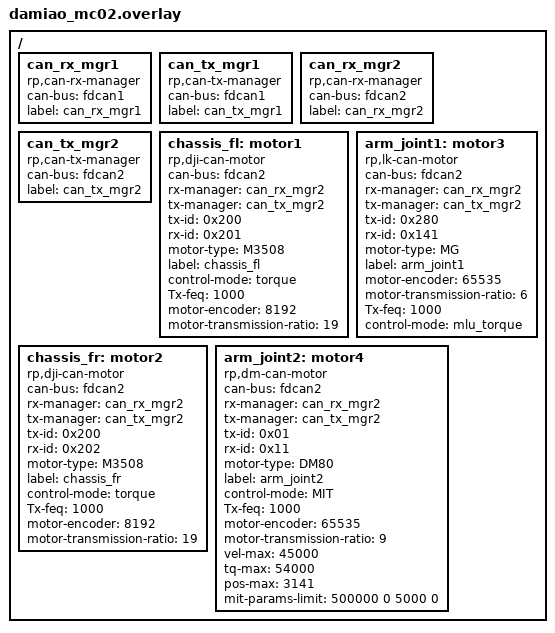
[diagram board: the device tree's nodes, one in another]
/*dts-test-motor*/
/ {
    can_rx_mgr1: can_rx_mgr1 {
        compatible = "rp,can-rx-manager";
        status = "okay";
        can-bus = <&fdcan1>;
        label = "can_rx_mgr1";
    };

    can_tx_mgr1: can_tx_mgr1 {
        compatible = "rp,can-tx-manager";
        status = "okay";
        can-bus = <&fdcan1>;
        label = "can_tx_mgr1";
    };

    can_rx_mgr2: can_rx_mgr2 {
        compatible = "rp,can-rx-manager";
        status = "okay";
        can-bus = <&fdcan2>;
        label = "can_rx_mgr2";
    };

    can_tx_mgr2: can_tx_mgr2 {
        compatible = "rp,can-tx-manager";
        status = "okay";
        can-bus = <&fdcan2>;
        label = "can_tx_mgr2";
    };

    chassis_fl:motor1{
        compatible = "rp,dji-can-motor";
        status = "okay";
        can-bus = <&fdcan2>;
        rx-manager = <&can_rx_mgr2>;
        tx-manager = <&can_tx_mgr2>;
        tx-id = <0x200>;
        rx-id = <0x201>;
        motor-type = "M3508";
        label = "chassis_fl";
        control-mode = "torque";
        Tx-feq = <1000>;
        motor-encoder = <8192>;
        motor-transmission-ratio = <19>;
    };

    chassis_fr:motor2{
        compatible = "rp,dji-can-motor";
        status = "okay";
        can-bus = <&fdcan2>;
        rx-manager = <&can_rx_mgr2>;
        tx-manager = <&can_tx_mgr2>;
        tx-id = <0x200>;
        rx-id = <0x202>;
        motor-type = "M3508";
        label = "chassis_fr";
        control-mode = "torque";
        Tx-feq = <1000>;
        motor-encoder = <8192>;
        motor-transmission-ratio = <19>;
    };

    arm_joint1:motor3{
        compatible = "rp,lk-can-motor";
        status = "okay";
        can-bus = <&fdcan2>;
        rx-manager = <&can_rx_mgr2>;
        tx-manager = <&can_tx_mgr2>;
        tx-id = <0x280>;
        rx-id = <0x141>;
        motor-type = "MG";
        label = "arm_joint1";
        motor-encoder = <65535>;
        motor-transmission-ratio = <6>;
        Tx-feq = <1000>;
        control-mode = "mlu_torque";
    };

    arm_joint2:motor4{
        compatible = "rp,dm-can-motor";
        status = "okay";
        can-bus = <&fdcan2>;
        rx-manager = <&can_rx_mgr2>;
        tx-manager = <&can_tx_mgr2>;
        tx-id = <0x01>;
        rx-id = <0x11>;
        motor-type = "DM80";
        label = "arm_joint2";
        control-mode = "MIT";
        Tx-feq = <1000>;
        motor-encoder = <65535>;
        motor-transmission-ratio = <9>;
        vel-max = <45000>;          // 这里的整数都要除以1000才是实际的上限，必须与上位机的值对应
        tq-max = <54000>;
        pos-max = <3141>;
        mit-params-limit = <500000 0 5000 0>;
    };

};
